# CY8C5868AXI_LP035 register map
File version: 0.1
CY8C58LP
Registers are 8-bit, read-write, no defined reset value unless marked. A register's access mark holds for its fields unless they carry their own. Offsets are from the block's base; lines under a group give offsets from that group; [hi:lo] are bit positions; {n}, {i} and the like mark numbered series; 'fields as' and 'values as' point back to an identical list; <NAME> marks a mode.

## Memory map
0x400043A3 Timer size 0xB64
0x400043A7 CapSense_CompCH0 size 0x17F0
0x400043A8 CapSense_IdacCH0 size 0x17DC
0x40006428 UART size 0x142
0x4000647E CapSense size 0x22

## Timer
Base 0x400043A3
0x00 Timer_GLOBAL_ENABLE — PM.ACT.CFG
  [3:0] en_timer — Enable timer/counters.
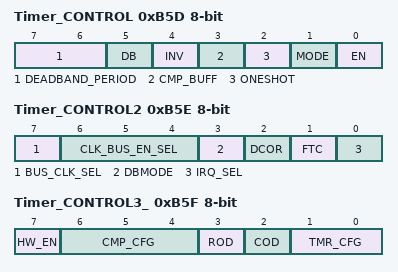
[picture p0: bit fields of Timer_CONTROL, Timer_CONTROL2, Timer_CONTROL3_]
0xB5D Timer_CONTROL — TMRx.CFG0
  [7:6] DEADBAND_PERIOD
  [5] DB — Deadband mode--Deadband phases phi1 and phi2 are outputted on CMP and TC output pins respectively.
    0=Timer (CMP and TC are output.); 1=Deadband (PHI1 (instead of CMP) and PHI2 (instead of TC) are output.)
  [4] INV — Invert sense of TIMEREN signal
  [3] CMP_BUFF — Buffer compare register. Compare register updates only on timer terminal count.
  [2] ONESHOT — Timer stops upon reaching stop condition defined by TMR_CFG bits. Can be restarted by asserting TIMER RESET or disabling and re-enabling block.
  [1] MODE — Mode. (0 = Timer; 1 = Comparator)
    0=Timer mode. CNT/CMP register holds timer count value.; 1=Comparator mode. CNT/CMP register holds comparator threshold value.
  [0] EN — Enables timer/comparator.
0xB5E Timer_CONTROL2 — TMRx.CFG1
  [7] BUS_CLK_SEL — Bus Clock selection.
  [6:4] CLK_BUS_EN_SEL — Digital Global Clock selection.
  [3] DBMODE — Deadband mode (asynchronous/synchronous). CMP output pin is also affected when not in deadband mode (CFG0.DEADBAND).
  [2] DCOR — Disable Clear on Read (DCOR) of Status Register SR0.
  [1] FTC — First Terminal Count (FTC). Setting this bit forces a single pulse on the TC pin when first enabled.
    0=Disable_FTC (Disable the single cycle pulse, which signifies the timer is starting.); 1=Enable_FTC (Enable the single cycle pulse, which signifies the timer is starting.)
  [0] IRQ_SEL — Irq selection. (0 = raw interrupts; 1 = status register interrupts)
0xB5F Timer_CONTROL3_ — TMRx.CFG2
  [7] HW_EN — When set Timer Enable controls counting.
  [6:4] CMP_CFG — Comparator configurations
    0=Equal (Compare Equal); 1=Less_than (Compare Less Than); 2=Less_than_or_equal (Compare Less Than or Equal .); 3=Greater (Compare Greater Than .); 4=Greater_than_or_equal (Compare Greater Than or Equal)
  [3] ROD — Reset On Disable (ROD). Resets internal state of output logic
  [2] COD — Clear On Disable (COD). Clears or gates outputs to zero.
  [1:0] TMR_CFG — Timer configuration (MODE = 0): 000 = Continuous; 001 = Pulsewidth; 010 = Period; 011 = Stop on IRQ
    0=Continuous (Timer runs while EN bit of CFG0 register is set to '1'.); 1=Pulsewidth (Timer runs from positive to negative edge of TIMEREN.); 2=Period (Timer runs from positive to positive edge of TIMEREN.); 3=Irq (Timer runs until IRQ.)
0xB61 Timer_PERIOD 16-bit — TMRx.PER0 - Assigned Period
0xB63 Timer_COUNTER 16-bit — TMRx.CNT_CMP0 - Current Down Counter Value

## CapSense
Base 0x4000647E
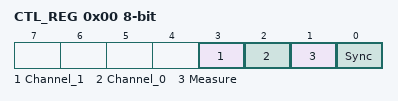
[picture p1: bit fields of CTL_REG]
0x00 CTL_REG
  [all] fields
    0=Disabled; 1=Enabled
  [3] Channel_1 ro
  [2] Channel_0 ro
  [1] Measure ro
  [0] Sync ro
0x11 ScanSpeed_PERIOD_REG
0x21 ScanSpeed_CTL_REG
  [3] Counter ro
    0=Disabled; 1=Enabled

## CapSense_IdacCH0
Base 0x400043A8
0x00 IDAC8_PM_ACT_CFG — Active Power Mode Configuration Register 8
  [3:0] en_dac — Enable DAC block(s). Populated subsystems are counted from the LSB.
0x10 IDAC8_PM_STBY_CFG — Standby Power Mode Configuration Register 8
  fields as IDAC8_PM_ACT_CFG
0x263 IDAC8_TR
  [7:0] tr — 8 Calibration bits
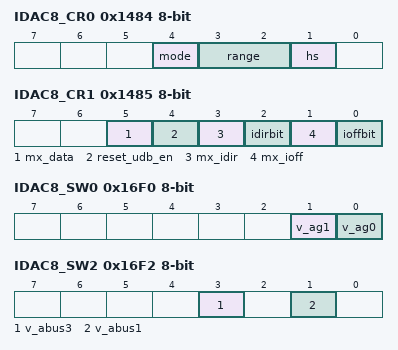
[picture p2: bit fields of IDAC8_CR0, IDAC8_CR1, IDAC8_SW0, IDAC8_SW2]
0x1484 IDAC8_CR0 — DAC Block Control Register 0
  [4] mode ro — Mode Bit
    0=DAC_MODE_V (voltage DAC); 1=DAC_MODE_I (current DAC)
  [3:2] range — Ranges for mode=0 (VDAC) and mode=1 (IDAC)
    0=DAC_RANGE_0 (x0=0V to 4*vref (1.024V); 0 to 31.875uA); 1=DAC_RANGE_1 (x1=0V to 16*vref (4.096V); 0 to 255uA); 2=DAC_RANGE_2 (x0=0V to 4*vref (1.024V); 0 to 2.040mA); 3=DAC_RANGE_3 (x1=0V to 16*vref (4.096V); not used)
  [1] hs — High Speed Bit
    0=DAC_HS_LOWPOWER (regular (low power)); 1=DAC_HS_HIGHSPEED (high speed (higher power))
0x1485 IDAC8_CR1 — DAC Block Control Register 1
  [5] mx_data — Select DATA source
    0=MX_DATA_REG (Select register source); 1=MX_DATA_UDB (Select UDB source)
  [4] reset_udb_en — DAC reset enable
    0=RESET_UDB_EN_DISABLE (Disable DAC Reset Source from UDB); 1=RESET_UDB_EN_ENABLE (Enable DAC Reset Source from UDB)
  [3] mx_idir — Mux selection for DAC current direction control
    0=MX_IDIR_REG (Register source idirbit selected); 1=MX_IDIR_UDB (UDB ictrl selected)
  [2] idirbit — register source for DAC current direction
  [1] mx_ioff — Mux selection for DAC current off control
    0=MX_IOFF_REG (Register source ioffbit selected); 1=MX_IOFF_UDB (UDB ictrl selected)
  [0] ioffbit — register source for DAC current off
0x16F0 IDAC8_SW0 — DAC Analog Routing Register 0
  [1] v_ag1 — Connect voltage output to analog global of same side
    0=AG_NC (not connected); 1=AG_CONNECTED (Connect to Analog Global)
  [0] v_ag0 — Connect voltage output to analog global of same side
    values as v_ag1
0x16F2 IDAC8_SW2 — DAC Analog Routing Register 2
  [3] v_abus3 — Connect voltage output to analog (local) bus of the same side
    0=ABUS_NC (not connected); 1=ABUS_CONNECTED (Connect to Analog (local) Bus)
  [1] v_abus1 — Connect voltage output to analog (local) bus of the same side
    values as v_abus3
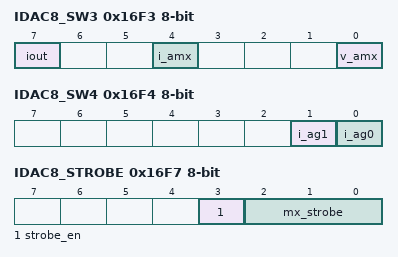
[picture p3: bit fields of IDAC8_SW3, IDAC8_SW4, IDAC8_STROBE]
0x16F3 IDAC8_SW3 — DAC Analog Routing Register 3
  [7] iout — Connect current output to pad
    0=IOUT_NC (not connected); 1=IOUT_CONNECT (Connect to pad)
  [4] i_amx — Connect current output to Analog Mux Bus
    0=AMX_NC (not connected); 1=AMX_CONNECTED (Connect to AMUXBUS)
  [0] v_amx — Connect voltage output to Analog Mux Bus
    values as i_amx
0x16F4 IDAC8_SW4 — DAC Analog Routing Register 4
  [1] i_ag1 — Connect current output to analog global of same side
    values as IDAC8_SW0.v_ag1
  [0] i_ag0 — Connect current output to analog global of same side
    values as IDAC8_SW0.v_ag1
0x16F7 IDAC8_STROBE — DAC Strobe Register
  [3] strobe_en — Strobe gating control
    0=disable strobe; 1=enable strobe
  [2:0] mx_strobe — Strobe source selection
    0=MX_STROBE_BUSWRITE (Select bus write strobe source); 1=MX_STROBE_UDB_SRC (Select UDB strobe source); 2=MX_STROBE_NC_2 (NC); 3=MX_STROBE_NC_3 (NC); {v}=MX_STROBE_CLK_A{v-4}_DIG (Select clk_a{v-4}_dig) (v=4..7)
0x17DB IDAC8_D — DAC Data Register
  [7:0] data — 8 DAC Data bits
